# wl_phy_mcu_secure register map
Vendor: Texas Instruments
Peripheral module from a debugger description file (folder CC35X1).
Registers are 32-bit, access per field, reset 0x0 unless marked. A register's access mark holds for its fields unless they carry their own. Offsets are as the file gives them; lines under a group give offsets from that group; [hi:lo] are bit positions; {n}, {i} and the like mark numbered series; 'fields as' and 'values as' point back to an identical list; <NAME> marks a mode.

## wl_phy_mcu_secure
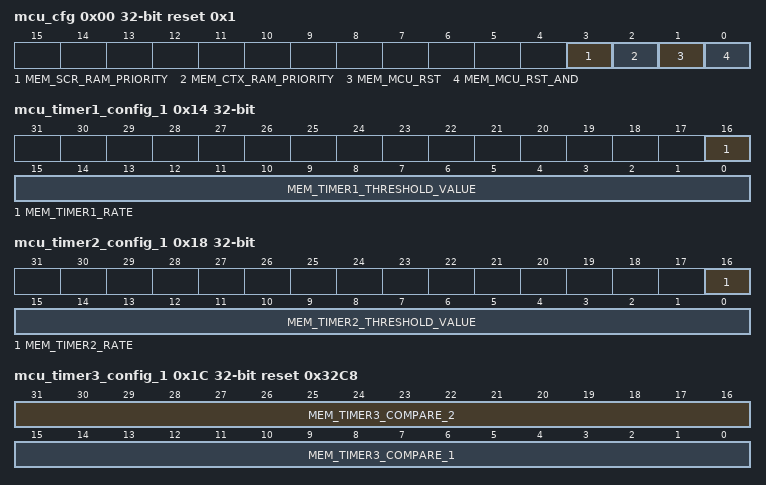
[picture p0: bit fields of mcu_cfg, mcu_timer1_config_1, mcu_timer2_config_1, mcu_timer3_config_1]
0x00 mcu_cfg reset 0x1
  [3] MEM_SCR_RAM_PRIORITY rw — Priority issued to SCR RAM Master Arbiter: 0 - SCR has priority when accessing SCR RAM, then CTX and then OCP IC 1 - CTX has priority when accessing SCR RAM, then SCR and then OCP IC
  [2] MEM_CTX_RAM_PRIORITY rw — Priority issued to CTX RAM Master Arbiter: 0 - CTX has priority when accessing CTX RAM 1 - OCP IC has priority when accessing CTX RAM
  [1] MEM_MCU_RST rw — Both MEM_MCU_RST_AND and MEM_MCU_RST have the same functionality but have different polarity (So basically, one of them is redundant) MCU_CFG[0]: '1' - Force cortex reset. '0' - do nothing. MCU_CFG[1]: '0' - Force cortex reset. '1' - do nothing. WSOC M3 Cortex Reset = HW_rst & mem_mcu_reset & ~mem_mcu_reset_and Where HW_rst is the global reset to the WLAN and reset both MAC and PHY with their registers file.
  [0] MEM_MCU_RST_AND rw — Both MEM_MCU_RST_AND and MEM_MCU_RST have the same functionality but have different polarity (So basically, one of them is redundant) MCU_CFG[0]: '1' - Force cortex reset. '0' - do nothing. MCU_CFG[1]: '0' - Force cortex reset. '1' - do nothing. WSOC M3 Cortex Reset = HW_rst & mem_mcu_reset & ~mem_mcu_reset_and Where HW_rst is the global reset to the WLAN and reset both MAC and PHY with their registers file.
{0x0+4i} mcu_spare_{i} rw (i=1..4)
  [31:0] MEM_MCU_SPARE_{i}
0x14 mcu_timer1_config_1 — Timer 1: An 16bit "2 event" count time Timer. Triggered by either FW or 8 HW maskable signals (rise or fall) Counts either @40M or @1M
  [16] MEM_TIMER1_RATE rw — This field set the timer count clock: 0 - 40M 1 - 1M (using usec_stb) Since timer size is 16bit 0 - Count max delay 64K*25ns=1.63msec at resolution of 25ns 1 - Count max delay 64K*1000ns=65.5msec at resolution of 1us
  [15:0] MEM_TIMER1_THRESHOLD_VALUE rw — When timer is triggerd it's counter will count up till reaching this value. Then send interrupt according to mask
0x18 mcu_timer2_config_1 — Timer 2: An 16bit "2 event" count time Timer. Triggered by either FW or 8 HW maskable signals (rise or fall) Counts either @40M or @1M
  [16] MEM_TIMER2_RATE rw — This field set the timer count clock: 0 - 40M 1 - 1M (using usec_stb) Since timer size is 16bit 0 - Count max delay 64K*25ns=1.63msec at resolution of 25ns 1 - Count max delay 64K*1000ns=65.5msec at resolution of 1us
  [15:0] MEM_TIMER2_THRESHOLD_VALUE rw — When timer is triggerd it's counter will count up till reaching this value. Then send interrupt according to mask
0x1C mcu_timer3_config_1 rw reset 0x32C8 — Timer 3: An 16bit "Rx timeout" Timer. SET by either FW or up to 4 HW maskable signals (rise or fall) RST by either FW or up to 8 HW maskable signals (rise or fall) Counts @1M to configurable value Two 2 configurable comparators (=exit points). *Upon its expiry, a reset will be performed by one of the executers (M0 or scripter), This is required to recover the system from Rx stuck situations.
  [31:16] MEM_TIMER3_COMPARE_2 — When timer is equal to this field - it set interrupt (depend on timer interrupt mask field)
  [15:0] MEM_TIMER3_COMPARE_1 — When timer is equal to this field - it set interrupt (depend on timer interrupt mask field)
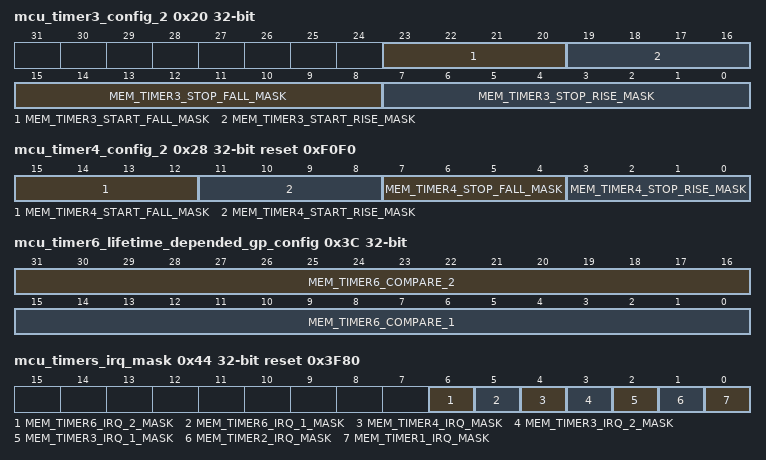
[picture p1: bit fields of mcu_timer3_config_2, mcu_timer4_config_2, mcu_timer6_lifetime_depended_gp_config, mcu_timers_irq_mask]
0x20 mcu_timer3_config_2 reset not defined — Timer 3 Trigger h/w sources are: timer3_start_hw_sources[ 3:0] = {1'b0,bs_rise,rxtb_bd_pulse,rx_bd}; timer3_stop_hw_sources [ 7:0] = {1'b0,tx_header_rise,rx_suspend_start,rx_stomp,rx_abort,rx_last,bs_fall,rx_ctrl_td_eop}; For Example: setting.. MEM_TIMER3_START_RISE_MASK[3:0] = 0xE; MEM_TIMER3_START_FALL_MASK[3:0] = 0xF; MEM_TIMER3_STOP_RISE_MASK[7:0] = 0xFE; MEM_TIMER3_STOP_FALL_MASK[7:0] = 0xFF; will casue timer trigger @rx_bd rise and Timer Disable @rx_ctrl_td_eop rise.
  [23:20] MEM_TIMER3_START_FALL_MASK rw — Each bit mask the correspondingly source index 1 - Start the timer uppon hw source falling edge 0 - Don't start timer uppon hw source falling edge
  [19:16] MEM_TIMER3_START_RISE_MASK rw — Each bit mask the correspondingly source index 1 - Start the timer uppon hw source rising edge 0 - Don't Start timer uppon hw source rising edge
  [15:8] MEM_TIMER3_STOP_FALL_MASK rw — Each bit mask the correspondingly source index 1 - Stop the timer uppon hw source falling edge 0 - Don't stop timer uppon hw source falling edge
  [7:0] MEM_TIMER3_STOP_RISE_MASK rw — Each bit mask the correspondingly source index 1 - Stop the timer uppon hw source rising edge 0 - Don't stop timer uppon hw source rising edge
0x24 mcu_timer4_config_1 reset 0x32C8 — Timer 4: An 16bit "Tx timeout" Timer. Counts @1M to configurable value Two 2 configurable comparators (=exit points). *Upon its expiry, a reset will be performed and the next state will be Rx search.
  [15:0] MEM_TIMER4_COMPARE rw — When timer is equal to this field - it set interrupt (depend on timer interrupt mask field)
0x28 mcu_timer4_config_2 reset 0xF0F0 — Timer 4 Trigger h/w sources are: timer4_start_hw_sources[0] = tx_header_rise; timer4_stop_hw_sources [0] = tx_active_fall; timer4_stop_hw_sources [1] = tx_abort_in_progressl; (few cycles) timer4_stop_hw_sources [2] = tx_active_ble_fall; For Example: setting.. MEM_TIMER4_STOP_RISE_MASK[3:0] = 0xE; MEM_TIMER4_STOP_FALL_MASK[3:0] = 0xF; MEM_TIMER4_START_RISE_MASK[3:0] = 0xE; MEM_TIMER4_START_FALL_MASK[3:0] = 0xF; will casue Timer trigger @"tx_header_rise" rise and Timer Disable @"tx_active_fall" rise.
  [15:12] MEM_TIMER4_START_FALL_MASK rw — 1 - Start the timer uppon hw source falling edge 0 - Don't start timer uppon hw source falling edge
  [11:8] MEM_TIMER4_START_RISE_MASK rw — 1 - Start the timer uppon hw source rising edge 0 - Don't Start timer uppon hw source rising edge
  [7:4] MEM_TIMER4_STOP_FALL_MASK rw — 1 - Stop the timer uppon hw source falling edge 0 - Don't stop timer uppon hw source falling edge
  [3:0] MEM_TIMER4_STOP_RISE_MASK rw — 1 - Stop the timer uppon hw source rising edge 0 - Don't stop timer uppon hw source rising edge
0x34 mcu_timer5_lifetime_value rw
  [31:0] MEM_TIMER5_VALUE_WROPT — Lifetime timer free running value
0x3C mcu_timer6_lifetime_depended_gp_config rw — Timer 6: A 16bit "Lifetime-dependet General Purpose" Timer. Counts in 1.024 ms resolution to two configurable values. The timer is depended on timer 5 (Lifetime), Timer clock is derived from timer 5 MSB's. IRQ upon compare Th 1 and/or compare Th 2 *Upon its expiry, a reset will be performed and the next state will be Rx search.
  [31:16] MEM_TIMER6_COMPARE_2 — When timer is equal to this field - it set interrupt (depend on timer interrupt mask field) value is in 1.024 msec units.
  [15:0] MEM_TIMER6_COMPARE_1 — When timer is equal to this field - it sets interrupt (depend on timer interrupt mask field) value is in 1.024 msec units.
0x44 mcu_timers_irq_mask reset 0x3F80 (reset mask 0xFFFFFF80) — Masks all times IRQ's
  [6] MEM_TIMER6_IRQ_2_MASK rw, [5] MEM_TIMER6_IRQ_1_MASK rw, [4] MEM_TIMER4_IRQ_MASK rw, [3] MEM_TIMER3_IRQ_2_MASK rw, [2] MEM_TIMER3_IRQ_1_MASK rw, [1] MEM_TIMER2_IRQ_MASK rw, [0] MEM_TIMER1_IRQ_MASK rw
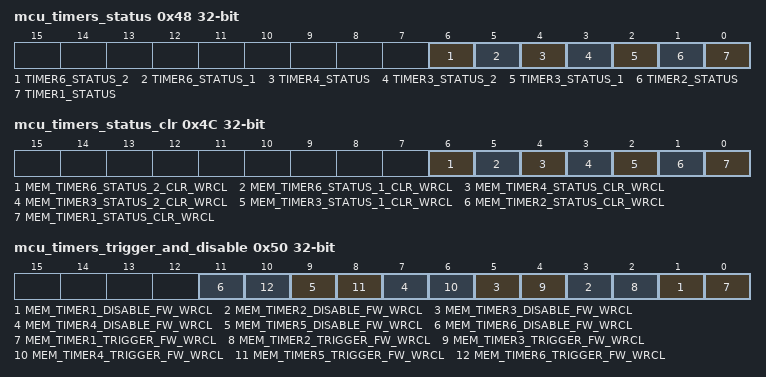
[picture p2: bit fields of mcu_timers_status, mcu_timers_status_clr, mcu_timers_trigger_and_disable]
0x48 mcu_timers_status ro — Points all timres status (status is set upon irq)
  [6] TIMER6_STATUS_2, [5] TIMER6_STATUS_1, [4] TIMER4_STATUS, [3] TIMER3_STATUS_2, [2] TIMER3_STATUS_1, [1] TIMER2_STATUS, [0] TIMER1_STATUS
0x4C mcu_timers_status_clr — Clears all timers status. These bits are clear on write (pulse)
  [6] MEM_TIMER6_STATUS_2_CLR_WRCL wo, [5] MEM_TIMER6_STATUS_1_CLR_WRCL wo, [4] MEM_TIMER4_STATUS_CLR_WRCL wo, [3] MEM_TIMER3_STATUS_2_CLR_WRCL wo, [2] MEM_TIMER3_STATUS_1_CLR_WRCL wo, [1] MEM_TIMER2_STATUS_CLR_WRCL wo, [0] MEM_TIMER1_STATUS_CLR_WRCL wo
0x50 mcu_timers_trigger_and_disable — trigger - reset timer value and run disable - pause and freeze timer value
  [2n-1] MEM_TIMER{n}_DISABLE_FW_WRCL wo (n=1..6) — Setting '1' will disable the timer This Register is self Cleared (clear on Write)
  [2n-2] MEM_TIMER{n}_TRIGGER_FW_WRCL wo (n=1..6) — Setting '1' will trigger the timer This Register is self Cleared (clear on Write)
0x60 mcu_subsys_spare reset 0x3
  [3:0] MEM_MCU_SUBSYS_SPARE rw — General MCU Sub system spare [0], [1] reset val = 1 [2], [3] reset val = 0
0x7C mcu_ocla_trigger — trigger - reset timer value and run disable - pause and freeze timer value
  [0] MEM_PHY_OCLA_TRIGGER_WRCL wo — Setting '1' will trigger ocla (PHY output to SOC OCLA)
